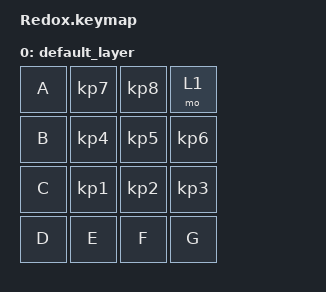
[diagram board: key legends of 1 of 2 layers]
#include <behaviors.dtsi>
#include <dt-bindings/zmk/keys.h>
#include <dt-bindings/zmk/bt.h>

/ {
    keymap {
        compatible = "zmk,keymap";

        default_layer {
            bindings = <
             &kp A   &kp KP_N7     &kp KP_N8     &mo 1
             &kp B   &kp KP_N4     &kp KP_N5     &kp KP_N6
             &kp C   &kp KP_N1     &kp KP_N2     &kp KP_N3
             &kp D   &kp E         &kp F         &kp G
            >;
        };

        bt_layer {
            bindings = <
            &none    &none            &none            &bootloader
            &none    &none            &none            &bt BT_CLR
            &none    &bt BT_SEL 0     &bt BT_SEL 1     &bt BT_SEL 2
            >;
        };
    };
};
